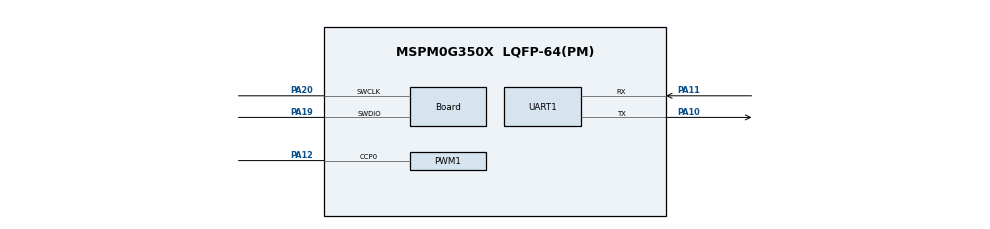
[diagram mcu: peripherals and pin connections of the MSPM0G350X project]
/**
 * @cliArgs --device "MSPM0G350X" --package "LQFP-64(PM)" --part "Default" --product "mspm0_sdk@1.30.00.03"
 * @versions {"tool":"1.19.0+3426"}
 */

/**
 * Import the modules used in this configuration.
 */
const GPIO          = scripting.addModule("/ti/driverlib/GPIO", {}, false);
const GPIO1         = GPIO.addInstance();
const GPIO2         = GPIO.addInstance();
const GPIO3         = GPIO.addInstance();
const PWM           = scripting.addModule("/ti/driverlib/PWM", {}, false);
const PWM1          = PWM.addInstance();
const SYSCTL        = scripting.addModule("/ti/driverlib/SYSCTL");
const TIMER         = scripting.addModule("/ti/driverlib/TIMER", {}, false);
const TIMER1        = TIMER.addInstance();
const UART          = scripting.addModule("/ti/driverlib/UART", {}, false);
const UART1         = UART.addInstance();
const ProjectConfig = scripting.addModule("/ti/project_config/ProjectConfig");

/**
 * Write custom configuration values to the imported modules.
 */
GPIO1.$name                          = "LED";
GPIO1.associatedPins.create(2);
GPIO1.associatedPins[0].$name        = "LEDR";
GPIO1.associatedPins[0].assignedPort = "PORTB";
GPIO1.associatedPins[0].assignedPin  = "18";
GPIO1.associatedPins[1].$name        = "LEDG";
GPIO1.associatedPins[1].assignedPort = "PORTB";
GPIO1.associatedPins[1].assignedPin  = "19";

const Board                       = scripting.addModule("/ti/driverlib/Board", {}, false);
Board.peripheral.$assign          = "DEBUGSS";
Board.peripheral.swclkPin.$assign = "PA20";
Board.peripheral.swdioPin.$assign = "PA19";

GPIO2.$name                          = "KEY";
GPIO2.associatedPins.create(2);
GPIO2.associatedPins[0].$name        = "KEY0";
GPIO2.associatedPins[0].assignedPort = "PORTA";
GPIO2.associatedPins[0].assignedPin  = "18";
GPIO2.associatedPins[0].direction    = "INPUT";
GPIO2.associatedPins[1].$name        = "KEY1";
GPIO2.associatedPins[1].assignedPort = "PORTB";
GPIO2.associatedPins[1].assignedPin  = "21";
GPIO2.associatedPins[1].direction    = "INPUT";

GPIO3.$name                          = "IIC";
GPIO3.associatedPins.create(2);
GPIO3.associatedPins[0].$name        = "SCL";
GPIO3.associatedPins[0].assignedPort = "PORTB";
GPIO3.associatedPins[0].assignedPin  = "14";
GPIO3.associatedPins[1].$name        = "SDA";
GPIO3.associatedPins[1].assignedPort = "PORTA";
GPIO3.associatedPins[1].assignedPin  = "30";

PWM1.clockDivider                       = 8;
PWM1.timerStartTimer                    = true;
PWM1.$name                              = "PWM_SG90";
PWM1.clockPrescale                      = 200;
PWM1.timerCount                         = 400;
PWM1.ccIndex                            = [0];
PWM1.peripheral.$assign                 = "TIMG0";
PWM1.peripheral.ccp0Pin.$assign         = "PA12";
PWM1.PWM_CHANNEL_0.$name                = "ti_driverlib_pwm_PWMTimerCC0";
PWM1.PWM_CHANNEL_0.invert               = true;
PWM1.ccp0PinConfig.direction            = scripting.forceWrite("OUTPUT");
PWM1.ccp0PinConfig.hideOutputInversion  = scripting.forceWrite(false);
PWM1.ccp0PinConfig.onlyInternalResistor = scripting.forceWrite(false);
PWM1.ccp0PinConfig.passedPeripheralType = scripting.forceWrite("Digital");
PWM1.ccp0PinConfig.$name                = "ti_driverlib_gpio_GPIOPinGeneric2";

SYSCTL.clockTreeEn = true;

TIMER1.$name            = "TIMER_0";
TIMER1.timerClkPrescale = 100;
TIMER1.timerMode        = "PERIODIC_UP";
TIMER1.interrupts       = ["ZERO"];
TIMER1.timerPeriod      = "20ms";

UART1.$name                    = "UART_0";
UART1.enabledInterrupts        = ["RX"];
UART1.peripheral.rxPin.$assign = "PA11";
UART1.peripheral.txPin.$assign = "PA10";
UART1.txPinConfig.$name        = "ti_driverlib_gpio_GPIOPinGeneric0";
UART1.rxPinConfig.$name        = "ti_driverlib_gpio_GPIOPinGeneric1";

ProjectConfig.deviceSpin = "MSPM0G3507";
scripting.suppress("Migrating requires going through the Switch Board or Device menu in the Device View section\\.", ProjectConfig, "deviceSpin");

/**
 * Pinmux solution for unlocked pins/peripherals. This ensures that minor changes to the automatic solver in a future
 * version of the tool will not impact the pinmux you originally saw.  These lines can be completely deleted in order to
 * re-solve from scratch.
 */
GPIO1.associatedPins[0].pin.$suggestSolution = "PB18";
GPIO1.associatedPins[1].pin.$suggestSolution = "PB19";
GPIO2.associatedPins[0].pin.$suggestSolution = "PA18";
GPIO2.associatedPins[1].pin.$suggestSolution = "PB21";
GPIO3.associatedPins[0].pin.$suggestSolution = "PB14";
GPIO3.associatedPins[1].pin.$suggestSolution = "PA30";
TIMER1.peripheral.$suggestSolution           = "TIMA0";
UART1.peripheral.$suggestSolution            = "UART0";
